# tviic2d6mddr register map
Vendor: Cypress Semiconductor; Series: tviic2d6mddr; File version: 1.0
CPU: CM7 r0p1, little endian, MPU, FPU, VTOR, 3 interrupt priority bits
Registers are 32-bit, read-write, reset 0x0 unless marked. A register's access mark holds for its fields unless they carry their own. Offsets are from the block's base; [hi:lo] are bit positions; lines under a group give offsets from that group; {n}, {i} and the like mark numbered series.

## LPDDR40 (part 2 of 5) — LPDDR4
Base 0x404A0000
0x1000 LPDDR4_CORE group — LPDDR4 core (3PIP)
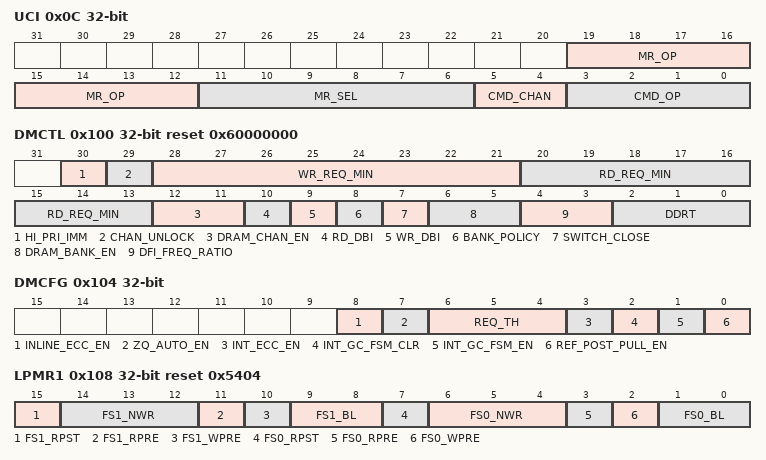
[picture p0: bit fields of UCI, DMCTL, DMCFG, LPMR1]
  0x0C UCI — User Command Interface
    [19:12] MR_OP — Register Opcode (MRW, MPC) See LPDDR4 memory datasheet for definition of opcodes.
    [11:6] MR_SEL — Register Select Argument for MRS/MRW/MRR Command
    [5:4] CMD_CHAN
    [3:0] CMD_OP — User Command Opcode. Valid values are: USER_CMD_STOP = 4'b0000 Stop Normal Operation USER_CMD_RUN = 4'b0001 Start Normal Operation USER_CMD_SRE = 4'b0010 Self-Refresh Mode Entry USER_CMD_SRX = 4'b0011 Self-Refresh Mode Exit USER_CMD_PDE = 4'b0100 Power-Down Mode Entry USER_CMD_PDX = 4'b0101 Power-Down Mode Exit USER_CMD_ZQRS = 4'b0110 ZQ Calibration Reset USER_CMD_MRR = 4'b0111 Mode Register Read USER_CMD_MRW = 4'b1000 Mode Register Write USER_CMD_BIST = 4'b1001 BIST USER_CMD_ZQSTART = 4'b1010 ZQSTART USER_CMD_ZQLAT = 4'b1011 ZQLAT USER_CMD_DQSOSC_START = 4'b1100 Start DQS Oscillator USER_CMD_DQSOSC_STOP = 4'b1101 Stop DQS Oscillator In case an invalid command or an invalid command sequence is detected the controller will enter STOP mode and raise a fault signal if dmcfg.int_gc_fsm_en is enabled.
  0x100 DMCTL reset 0x60000000 — Dynamo Control Register
    [30] HI_PRI_IMM — High priority immediately serving. The Arbiter will grant for the high priority stream immediately. 0: Disabled 1: Enabled
    [29] CHAN_UNLOCK — Channel unlock. A bank requester FSM can be unlocked while it is blocked by the other in the same port. 0: Disabled 1: Enabled
    [28:21] WR_REQ_MIN — Minimum Available Write requests will be served before switching to Read direction
    [20:13] RD_REQ_MIN — Minimum Available Read requests will be served before switching to Write direction
    [12:11] DRAM_CHAN_EN
    [10] RD_DBI — Memory Controller Read Databus Inversion (DBI) Mode Enable/disable coding: DISABLE = 0 Disable this feature ENABLE = 1 Enable this feature
    [9] WR_DBI — Memory Controller Write Databus Inversion (DBI) Mode Enable/disable coding: DISABLE = 0 Disable this feature ENABLE = 1 Enable this feature
    [8] BANK_POLICY — CLOSE_PAGE = 0 Close Page Policy OPEN_PAGE = 1 Open page policy
    [7] SWITCH_CLOSE — Force closing open page when Read/Write direction changes. DONT_CLOSE_ON_RW_CHG = 0 Do not close an open page when Read/Write direction changes on the same page. DO_CLOSE_ON_RW_CHG = 1 Close an open page when Read/Write direction changes on the same page.
    [6:5] DRAM_BANK_EN
    [4:3] DFI_FREQ_RATIO — DFI Frequency Ratio Always write 2'b10 to this register (only frequency ratio 1:4 is supported). DIV_4 = 2'b10 Controller to PHY frequency ratio is 1:4.
    [2:0] DDRT — DDR Type. Always write 3'b111 for LPDDR4. Only LPDDR4 is supported. LPDDR4 = 3'b111 LPDDR4
  0x104 DMCFG — Dynamo Configuration Register
    [8] INLINE_ECC_EN — Inline ECC enable. Enable/disable coding: DISABLE = 0 Disable this feature ENABLE = 1 Enable this feature
    [7] ZQ_AUTO_EN — Automatic ZQ Calibration enable. In case Automatic ZQ Calibration is used, the rate is defined in TREG9.T_ZQ_ITV. Enable/disable coding: DISABLE = 0 Disable this feature ENABLE = 1 Enable this feature
    [6:4] REQ_TH — Look-ahead buffer request threshold
    [3] INT_ECC_EN — ECC interrupt enable signal. Enable/disable coding: DISABLE = 0 Disable this feature ENABLE = 1 Enable this feature
    [2] INT_GC_FSM_CLR — Global FSM Error interrupt clear signal. DONT_CLEAR = 0 Don't clear. DO_CLEAR = 1 Clear. Set int_gc_fsm LOW.
    [1] INT_GC_FSM_EN — Global FSM Error interrupt enable signal. Enable/disable coding: DISABLE = 0 Disable this feature ENABLE = 1 Enable this feature
    [0] REF_POST_PULL_EN — Enables Postpone/Pull Automatic Refresh. Enable/disable coding: DISABLE = 0 Disable this feature ENABLE = 1 Enable this feature
  0x108 LPMR1 reset 0x5404 — LPDDR Mode Register 1
    [15] FS1_RPST — Read postamble for frequency set 1 Read Postamble values according to JESD209-4: RD_POSTAMBLE_0P5 = 0B RD Post-amble = 0.5*tCK (default) RD_POSTAMBLE_1P5 = 1B RD Post-amble = 1.5*tCK
    [14:12] FS1_NWR — Write recovery to pre-charge for frequency set 1 Write Recovery values according to JESD209-4: NWR6 = 000B nWR = 6 (default) NWR10 = 001B nWR = 10 NWR16 = 010B nWR = 16 NWR20 = 011B nWR = 20 NWR24 = 100B nWR = 24 NWR30 = 101B nWR = 30 NWR34 = 110B nWR = 34 NWR40 = 111B nWR = 40
    [11] FS1_RPRE — Read preamble for frequency set 1 Read Preamble values according to JESD209-4: RD_PREAMBLE_STATIC = 0B RD Pre-amble = Static (default) RD_PREAMBLE_TOGGLE = 1B RD Pre-amble = Toggle
    [10] FS1_WPRE
    [9:8] FS1_BL
    [7] FS0_RPST — Read postamble for frequency set 0 Read Postamble values according to JESD209-4: RD_POSTAMBLE_0P5 = 0B RD Post-amble = 0.5*tCK (default) RD_POSTAMBLE_1P5 = 1B RD Post-amble = 1.5*tCK
    [6:4] FS0_NWR — Write recovery to pre-charge for frequency set 0 Write Recovery values according to JESD209-4: NWR6 = 000B nWR = 6 (default) NWR10 = 001B nWR = 10 NWR16 = 010B nWR = 16 NWR20 = 011B nWR = 20 NWR24 = 100B nWR = 24 NWR30 = 101B nWR = 30 NWR34 = 110B nWR = 34 NWR40 = 111B nWR = 40
    [3] FS0_RPRE — Read preamble for frequency set 0 Read Preamble values according to JESD209-4: RD_PREAMBLE_STATIC = 0B RD Pre-amble = Static (default) RD_PREAMBLE_TOGGLE = 1B RD Pre-amble = Toggle
    [2] FS0_WPRE
    [1:0] FS0_BL
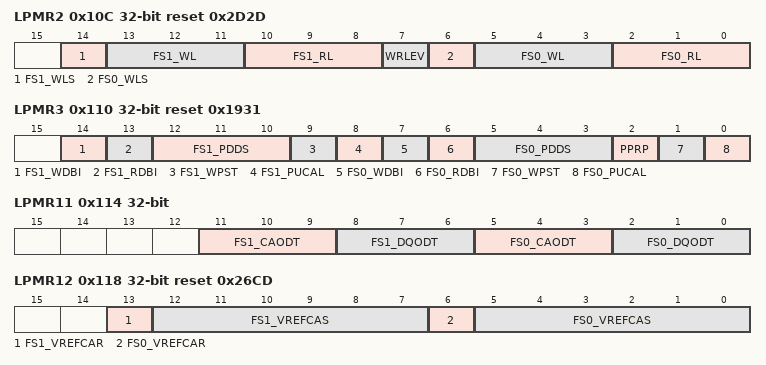
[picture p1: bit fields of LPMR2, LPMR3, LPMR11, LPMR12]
  0x10C LPMR2 reset 0x2D2D — LPDDR Mode Register 2
    [14] FS1_WLS — Write Latency Set values according to JESD209-4: WL_SET_A = 0B WL Set 'A' (default) WL_SET_B = 1B WL Set 'B'
    [13:11] FS1_WL — Write latency for frequency set 1 Write Latency values according to JESD209-4: WL Set 'A' (MR2 OP[6]=0B) 000B: WL=4 (Default) 001B: WL=6 010B: WL=8 011B: WL=10 100B: WL=12 101B: WL=14 110B: WL=16 111B: WL=18 WL Set 'B' (MR2 OP[6]=1B) 000B: WL=4 001B: WL=8 010B: WL=12 011B: WL=18 100B: WL=22 101B: WL=26 110B: WL=30 111B: WL=34
    [10:8] FS1_RL — Read latency for frequency set 1 Read Latency values according to JESD209-4: RL & nRTP for DBI-RD Disabled (MR3 OP[6]=0B) 000B: RL=6, nRTP = 8 (Default) 001B: RL=10, nRTP = 8 010B: RL=14, nRTP = 8 011B: RL=20, nRTP = 8 100B: RL=24, nRTP = 10 101B: RL=28, nRTP = 12 110B: RL=32, nRTP = 14 111B: RL=36, nRTP = 16 RL & nRTP for DBI-RD Enabled (MR3 OP[6]=1B) 000B: RL=6, nRTP = 8 001B: RL=12, nRTP = 8 010B: RL=16, nRTP = 8 011B: RL=22, nRTP = 8 100B: RL=28, nRTP = 10 101B: RL=32, nRTP = 12 110B: RL=36, nRTP = 14 111B: RL=40, nRTP = 16
    [7] WRLEV — Write Leveling Enable Enable/disable coding: DISABLE = 0 Disable this feature ENABLE = 1 Enable this feature
    [6] FS0_WLS — Write Latency Set values according to JESD209-4: WL_SET_A = 0B WL Set 'A' (default) WL_SET_B = 1B WL Set 'B'
    [5:3] FS0_WL — Write latency for frequency set 0 Write Latency values according to JESD209-4: WL Set 'A' (MR2 OP[6]=0B) 000B: WL=4 (Default) 001B: WL=6 010B: WL=8 011B: WL=10 100B: WL=12 101B: WL=14 110B: WL=16 111B: WL=18 WL Set 'B' (MR2 OP[6]=1B) 000B: WL=4 001B: WL=8 010B: WL=12 011B: WL=18 100B: WL=22 101B: WL=26 110B: WL=30 111B: WL=34
    [2:0] FS0_RL — Read latency for frequency set 0 Read Latency values according to JESD209-4: RL & nRTP for DBI-RD Disabled (MR3 OP[6]=0B) 000B: RL=6, nRTP = 8 (Default) 001B: RL=10, nRTP = 8 010B: RL=14, nRTP = 8 011B: RL=20, nRTP = 8 100B: RL=24, nRTP = 10 101B: RL=28, nRTP = 12 110B: RL=32, nRTP = 14 111B: RL=36, nRTP = 16 RL & nRTP for DBI-RD Enabled (MR3 OP[6]=1B) 000B: RL=6, nRTP = 8 001B: RL=12, nRTP = 8 010B: RL=16, nRTP = 8 011B: RL=22, nRTP = 8 100B: RL=28, nRTP = 10 101B: RL=32, nRTP = 12 110B: RL=36, nRTP = 14 111B: RL=40, nRTP = 16
  0x110 LPMR3 reset 0x1931 — LPDDR Mode Register 3
    [14] FS1_WDBI — Write DBI mode for frequency set 1 Values according to JESD209-4: Enable/disable coding: DISABLE = 0 Disable this feature ENABLE = 1 Enable this feature
    [13] FS1_RDBI — Read DBI mode for frequency set 1 Values according to JESD209-4: Enable/disable coding: DISABLE = 0 Disable this feature ENABLE = 1 Enable this feature
    [12:10] FS1_PDDS
    [9] FS1_WPST — Write post-amble for frequency set 1 Write post-amble values according to JESD209-4: WR_POSTAMBLE_0P5 = 0B WR Post-amble = 0.5*tCK (default) WR_POSTAMBLE_1P5 = 1B WR Post-amble = 1.5*tCK (Vendor specific function)
    [8] FS1_PUCAL — Pull-up Calibration point for frequency set 1 Pull-up Calibration point values according to JESD209-4: VDDQ_DIV_2P5 = 0B VDDQ/2.5 VDDQ_DIV_3 = 1B VDDQ/3 (default)
    [7] FS0_WDBI — Write DBI mode for frequency set 0 Values according to JESD209-4: Enable/disable coding: DISABLE = 0 Disable this feature ENABLE = 1 Enable this feature
    [6] FS0_RDBI — Read DBI mode for frequency set 0 Values according to JESD209-4: Enable/disable coding: DISABLE = 0 Disable this feature ENABLE = 1 Enable this feature
    [5:3] FS0_PDDS
    [2] PPRP — Post package repair protection Values according to JESD209-4: Enable/disable coding: DISABLE = 0 Disable this feature ENABLE = 1 Enable this feature
    [1] FS0_WPST — Write post-amble for frequency set 0 Write post-amble values according to JESD209-4: WR_POSTAMBLE_0P5 = 0B WR Post-amble = 0.5*tCK (default) WR_POSTAMBLE_1P5 = 1B WR Post-amble = 1.5*tCK (Vendor specific function)
    [0] FS0_PUCAL — Pull-up Calibration point for frequency set 0 Pull-up Calibration point values according to JESD209-4: VDDQ_DIV_2P5 = 0B VDDQ/2.5 VDDQ_DIV_3 = 1B VDDQ/3 (default)
  0x114 LPMR11 — LPDDR Mode Register 11
    [11:9] FS1_CAODT, [8:6] FS1_DQODT, [5:3] FS0_CAODT, [2:0] FS0_DQODT
  0x118 LPMR12 reset 0x26CD — LPDDR Mode Register 12
    [13] FS1_VREFCAR — VREF-CA range for frequency set 1 VREF Range according to JESD209-4: RANGE0 = 0B Range[0] enabled RANGE1 =1B Range[1] enabled
    [12:7] FS1_VREFCAS — VREF-CA Settings for frequency set 1 VREF-CA Setting values according to JESD209-4: See JESD209-4B Table 13 - VREF Settings for Range[0] and Range[1]
    [6] FS0_VREFCAR — VREF-CA range for frequency set 0 VREF Range according to JESD209-4: RANGE0 = 0B Range[0] enabled RANGE1 =1B Range[1] enabled
    [5:0] FS0_VREFCAS — VREF-CA Settings for frequency set 0 VREF-CA Setting values according to JESD209-4: See JESD209-4B Table 13 - VREF Settings for Range[0] and Range[1]
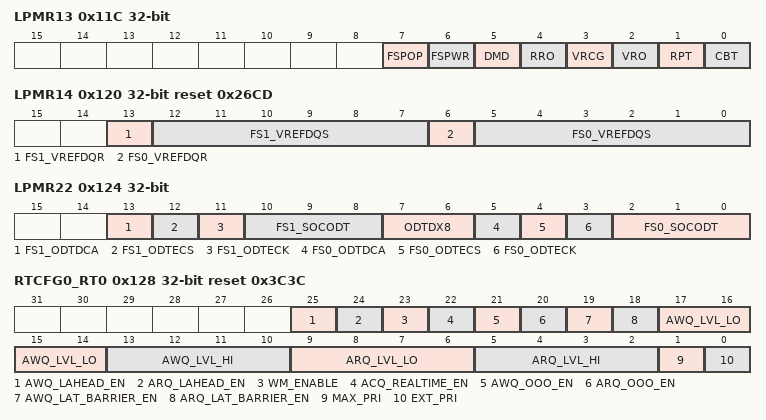
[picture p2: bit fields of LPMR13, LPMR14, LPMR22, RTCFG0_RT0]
  0x11C LPMR13 — LPDDR Mode Register 13
    [7] FSPOP — Frequency Set Point operating mode Frequency Set Point coding according to JESD209-4: FSP0 = 0 Frequency Set Point 0 FSP1 = 1 Frequency Set Point 1
    [6] FSPWR — Frequency Set Point write enable Frequency Set Point coding according to JESD209-4: FSP0 = 0 Frequency Set Point 0 FSP1 = 1 Frequency Set Point 1
    [5] DMD — Data mask disable Data Mask Disable values according to JESD209-4: ENABLED = 0B Data Mask Operation Enabled (default) DISABLED = 1B Data Mask Operation Disabled
    [4] RRO — Refresh rate option Refresh Rate Option values according to JESD209-4: DISABLE_RR4X2X = 0B Disable codes 001 (Refresh Rate x 4) and 010 (Refresh Rate x 2) in MR4 OP[2:0] ENABLE_ALL = 1B Enable all codes in MR4 OP[2:0]
    [3] VRCG — VREF current generator VREF Current Generator values according to JESD209-4: NORMAL = 0B Normal Operation (default) VREF_FAST = 1B VREF Fast Response (high current) mode
    [2] VRO — VREF output enable Enable/disable coding: DISABLE = 0 Disable this feature ENABLE = 1 Enable this feature
    [1] RPT — Read preamble training mode Values according to JESD209-4: Enable/disable coding: DISABLE = 0 Disable this feature ENABLE = 1 Enable this feature
    [0] CBT — Command bus training mode enable Enable/disable coding: DISABLE = 0 Disable this feature ENABLE = 1 Enable this feature
  0x120 LPMR14 reset 0x26CD — LPDDR Mode Register 14
    [13] FS1_VREFDQR — VREF-DQ range for frequency set 1 VREF Range according to JESD209-4: RANGE0 = 0B Range[0] enabled RANGE1 =1B Range[1] enabled
    [12:7] FS1_VREFDQS — VREF-DQ Settings for frequency set 1 VREF-DQ Setting values according to JESD209-4: See JESD209-4B Table 14 - VREF Settings for Range[0] and Range[1]
    [6] FS0_VREFDQR — VREF-DQ range for frequency set 0 VREF Range according to JESD209-4: RANGE0 = 0B Range[0] enabled RANGE1 =1B Range[1] enabled
    [5:0] FS0_VREFDQS — VREF-DQ Settings for frequency set 0 VREF-DQ Setting values according to JESD209-4: See JESD209-4B Table 14 - VREF Settings for Range[0] and Range[1]
  0x124 LPMR22 — LPDDR Mode Register 22
    [13] FS1_ODTDCA — ODTD-CA. CA ODT termination disable for frequency set 1 Command/Address bus ODT termination disable. Values according to JESD209-4: ODT_CA_PAD = 0B ODT-CA Obeys ODT_CA bond pad (default) ODT_CA_DISABLED = 1B ODT-CA Disabled
    [12] FS1_ODTECS — ODTE-CS. CS ODT enable for non-terminating rank for frequency set 1 ODT Enable for non-terminating rank. Values according to JESD209-4: OVERRIDE_DISABLED = 0B ODT-CK Over-ride Disabled (Default) OVERRIDE_ENABLED = 1B ODT-CK Over-ride Enabled
    [11] FS1_ODTECK — ODTE-CK. CK ODT enable for non-terminating rank for frequency set 1 ODT Enable for non-terminating rank. Values according to JESD209-4: OVERRIDE_DISABLED = 0B ODT-CK Over-ride Disabled (Default) OVERRIDE_ENABLED = 1B ODT-CK Over-ride Enabled
    [10:8] FS1_SOCODT — SoC ODT. Controller ODT value for VOH calibration for frequency set 1 Controller ODT values according to JESD209-4: DISABLE = 000B Disable (Default) RZQ_DIV_1 = 001B RZQ/1 RZQ_DIV_2 = 010B RZQ/2 RZQ_DIV_3 = 011B RZQ/3 RZQ_DIV_4 = 100B RZQ/4 RZQ_DIV_5 = 101B RZQ/5 RZQ_DIV_6 = 110B RZQ/6 RFU = 111B RFU
    [7:6] ODTDX8 — ODTD for x8_2ch (byte) mode
    [5] FS0_ODTDCA — ODTD-CA. CA ODT termination disable for frequency set 0 Command/Address bus ODT termination disable. Values according to JESD209-4: ODT_CA_PAD = 0B ODT-CA Obeys ODT_CA bond pad (default) ODT_CA_DISABLED = 1B ODT-CA Disabled
    [4] FS0_ODTECS — ODTE-CS. CS ODT enable for non-terminating rank for frequency set 0 ODT Enable for non-terminating rank. Values according to JESD209-4: OVERRIDE_DISABLED = 0B ODT-CK Over-ride Disabled (Default) OVERRIDE_ENABLED = 1B ODT-CK Over-ride Enabled
    [3] FS0_ODTECK — ODTE-CK. CK ODT enable for non-terminating rank for frequency set 0 ODT Enable for non-terminating rank. Values according to JESD209-4: OVERRIDE_DISABLED = 0B ODT-CK Over-ride Disabled (Default) OVERRIDE_ENABLED = 1B ODT-CK Over-ride Enabled
    [2:0] FS0_SOCODT — SoC ODT. Controller ODT value for VOH calibration for frequency set 0 Controller ODT values according to JESD209-4: DISABLE = 000B Disable (Default) RZQ_DIV_1 = 001B RZQ/1 RZQ_DIV_2 = 010B RZQ/2 RZQ_DIV_3 = 011B RZQ/3 RZQ_DIV_4 = 100B RZQ/4 RZQ_DIV_5 = 101B RZQ/5 RZQ_DIV_6 = 110B RZQ/6 RFU = 111B RFU
  0x128 RTCFG0_RT0 reset 0x3C3C — Route Configuration 0 - Route 0
    [25] AWQ_LAHEAD_EN — Out of order enable for Look-ahead buffer in Write channel - Route 0
    [24] ARQ_LAHEAD_EN — Out of order enable for Look-ahead buffer in read channel - Route 0
    [23] WM_ENABLE — Masked Write Support - Route 0 Enable/disable coding: DISABLE = 0 Disable this feature ENABLE = 1 Enable this feature
    [22] ACQ_REALTIME_EN — Realtime priority enable for Read/Write channel - Route 0 Enable/disable coding: DISABLE = 0 Disable this feature ENABLE = 1 Enable this feature
    [21] AWQ_OOO_EN — Out of order enable for write channel - Route 0 Enable/disable coding: DISABLE = 0 Disable this feature ENABLE = 1 Enable this feature
    [20] ARQ_OOO_EN — Out of order enable for read channel - Route 0 Enable/disable coding: DISABLE = 0 Disable this feature ENABLE = 1 Enable this feature
    [19] AWQ_LAT_BARRIER_EN — Maximum Latency Barrier Enable for Write Channel - Route 0 Enable/disable coding: DISABLE = 0 Disable this feature ENABLE = 1 Enable this feature
    [18] ARQ_LAT_BARRIER_EN — Maximum Latency Barrier Enable for Read Channel - Route 0 Enable/disable coding: DISABLE = 0 Disable this feature ENABLE = 1 Enable this feature
    [17:14] AWQ_LVL_LO — Denotes Write Address Queue Low Priority Threshold - Route 0
    [13:10] AWQ_LVL_HI — Denotes Write Address Queue High Priority Threshold - Route 0
    [9:6] ARQ_LVL_LO — Denotes Read Address Queue Low Priority Threshold - Route 0
    [5:2] ARQ_LVL_HI — Denotes Read Address Queue High Priority Threshold - Route 0
    [1] MAX_PRI — Denotes Static Maximum Priority - Route 0 Enable/disable coding: DISABLE = 0 Disable this feature ENABLE = 1 Enable this feature
    [0] EXT_PRI — Selects whether to use external AXI QoS field or internal combination of static and dynamic priority. STATIC_DYNAMIC = 0 Internal Static or Dynamic Priority used AXI_QOS = 1 AXI QoS used
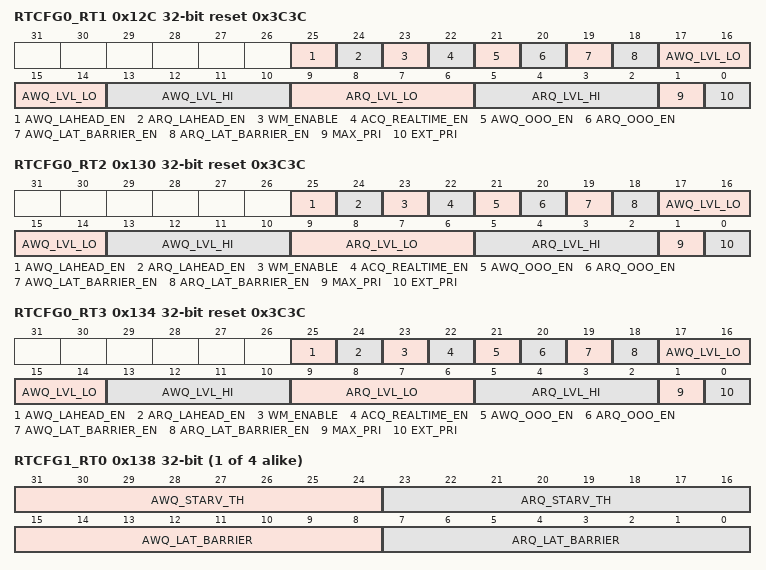
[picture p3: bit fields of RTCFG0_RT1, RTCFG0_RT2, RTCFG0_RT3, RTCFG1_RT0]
  0x12C RTCFG0_RT1 reset 0x3C3C — Route Configuration 0 - Route 1
    [25] AWQ_LAHEAD_EN — Out of order enable for Look-ahead buffer in Write channel - Route 1
    [24] ARQ_LAHEAD_EN — Out of order enable for Look-ahead buffer in read channel - Route 1
    [23] WM_ENABLE — Masked Write Support - Route 1 Enable/disable coding: DISABLE = 0 Disable this feature ENABLE = 1 Enable this feature
    [22] ACQ_REALTIME_EN — Realtime priority enable for Read/Write channel - Route 1 Enable/disable coding: DISABLE = 0 Disable this feature ENABLE = 1 Enable this feature
    [21] AWQ_OOO_EN — Out of order enable for write channel - Route 1 Enable/disable coding: DISABLE = 0 Disable this feature ENABLE = 1 Enable this feature
    [20] ARQ_OOO_EN — Out of order enable for read channel - Route 1 Enable/disable coding: DISABLE = 0 Disable this feature ENABLE = 1 Enable this feature
    [19] AWQ_LAT_BARRIER_EN — Maximum Latency Barrier Enable for Write Channel - Route 1Enable/disable coding: DISABLE = 0 Disable this feature ENABLE = 1 Enable this feature
    [18] ARQ_LAT_BARRIER_EN — Maximum Latency Barrier Enable for Read Channel - Route 1 Enable/disable coding: DISABLE = 0 Disable this feature ENABLE = 1 Enable this feature
    [17:14] AWQ_LVL_LO — Denotes Write Address Queue Low Priority Threshold - Route 1
    [13:10] AWQ_LVL_HI — Denotes Write Address Queue High Priority Threshold - Route 1
    [9:6] ARQ_LVL_LO — Denotes Read Address Queue Low Priority Threshold - Route 1
    [5:2] ARQ_LVL_HI — Denotes Read Address Queue High Priority Threshold - Route 1
    [1] MAX_PRI — Denotes Static Maximum Priority - Route 1 Enable/disable coding: DISABLE = 0 Disable this feature ENABLE = 1 Enable this feature
    [0] EXT_PRI — Selects whether to use external AXI QoS field or internal combination of static and dynamic priority - Route 1 Enable/disable coding: DISABLE = 0 Disable this feature ENABLE = 1 Enable this feature
  0x130 RTCFG0_RT2 reset 0x3C3C — Route Configuration 0 - Route 2
    [25] AWQ_LAHEAD_EN — Out of order enable for Look-ahead buffer in Write channel - Route 2
    [24] ARQ_LAHEAD_EN — Out of order enable for Look-ahead buffer in read channel - Route 2
    [23] WM_ENABLE — Masked Write Support - Route 2 Enable/disable coding: DISABLE = 0 Disable this feature ENABLE = 1 Enable this feature
    [22] ACQ_REALTIME_EN — Realtime priority enable for Read/Write channel - Route 2 Enable/disable coding: DISABLE = 0 Disable this feature ENABLE = 1 Enable this feature
    [21] AWQ_OOO_EN — Out of order enable for write channel - Route 2 Enable/disable coding: DISABLE = 0 Disable this feature ENABLE = 1 Enable this feature
    [20] ARQ_OOO_EN — Out of order enable for read channel - Route 2 Enable/disable coding: DISABLE = 0 Disable this feature ENABLE = 1 Enable this feature
    [19] AWQ_LAT_BARRIER_EN — Maximum Latency Barrier Enable for Write Channel - Route 2 Enable/disable coding: DISABLE = 0 Disable this feature ENABLE = 1 Enable this feature
    [18] ARQ_LAT_BARRIER_EN — Maximum Latency Barrier Enable for Read Channel - Route 2 Enable/disable coding: DISABLE = 0 Disable this feature ENABLE = 1 Enable this feature
    [17:14] AWQ_LVL_LO — Denotes Write Address Queue Low Priority Threshold - Route 2
    [13:10] AWQ_LVL_HI — Denotes Write Address Queue High Priority Threshold - Route 2
    [9:6] ARQ_LVL_LO — Denotes Read Address Queue Low Priority Threshold - Route 2
    [5:2] ARQ_LVL_HI — Denotes Read Address Queue High Priority Threshold - Route 2
    [1] MAX_PRI — Denotes Static Maximum Priority - Route 2 Enable/disable coding: DISABLE = 0 Disable this feature ENABLE = 1 Enable this feature
    [0] EXT_PRI — Selects whether to use external AXI QoS field or internal combination of static and dynamic priority - Route 2 Enable/disable coding: DISABLE = 0 Disable this feature ENABLE = 1 Enable this feature
  0x134 RTCFG0_RT3 reset 0x3C3C — Route Configuration 0 - Route 3
    [25] AWQ_LAHEAD_EN — Out of order enable for Look-ahead buffer in Write channel - Route 3
    [24] ARQ_LAHEAD_EN — Out of order enable for Look-ahead buffer in read channel - Route 3
    [23] WM_ENABLE — Masked Write Support - Route 3 Enable/disable coding: DISABLE = 0 Disable this feature ENABLE = 1 Enable this feature
    [22] ACQ_REALTIME_EN — Realtime priority enable for Read/Write channel - Route 3 Enable/disable coding: DISABLE = 0 Disable this feature ENABLE = 1 Enable this feature
    [21] AWQ_OOO_EN — Out of order enable for write channel - Route 3 Enable/disable coding: DISABLE = 0 Disable this feature ENABLE = 1 Enable this feature
    [20] ARQ_OOO_EN — Out of order enable for read channel - Route 3 Enable/disable coding: DISABLE = 0 Disable this feature ENABLE = 1 Enable this feature
    [19] AWQ_LAT_BARRIER_EN — Maximum Latency Barrier Enable for Write Channel - Route 3 Enable/disable coding: DISABLE = 0 Disable this feature ENABLE = 1 Enable this feature
    [18] ARQ_LAT_BARRIER_EN — Maximum Latency Barrier Enable for Read Channel - Route 3 Enable/disable coding: DISABLE = 0 Disable this feature ENABLE = 1 Enable this feature
    [17:14] AWQ_LVL_LO — Denotes Write Address Queue Low Priority Threshold - Route 3
    [13:10] AWQ_LVL_HI — Denotes Write Address Queue High Priority Threshold - Route 3
    [9:6] ARQ_LVL_LO — Denotes Read Address Queue Low Priority Threshold - Route 3
    [5:2] ARQ_LVL_HI — Denotes Read Address Queue High Priority Threshold - Route 3
    [1] MAX_PRI — Denotes Static Maximum Priority - Route 3 Enable/disable coding: DISABLE = 0 Disable this feature ENABLE = 1 Enable this feature
    [0] EXT_PRI — Selects whether to use external AXI QoS field or internal combination of static and dynamic priority - Route 3 Enable/disable coding: DISABLE = 0 Disable this feature ENABLE = 1 Enable this feature
  {0x138+4j} RTCFG1_RT{j} (j=0..3) — Route Configuration 1 - Route {j}
    [31:24] AWQ_STARV_TH — Denotes Write Address Queue Threshold for starvation preventing. Its value represents the number of hits in a hit chain - Route {j}
    [23:16] ARQ_STARV_TH — Denotes Read Address Queue Threshold for starvation preventing. Its value represents the number of hits in a hit chain - Route {j}
    [15:8] AWQ_LAT_BARRIER — Maximum Latency Barrier for Write Channel - Route {j}
    [7:0] ARQ_LAT_BARRIER — Maximum Latency Barrier for Read Channel - Route {j}
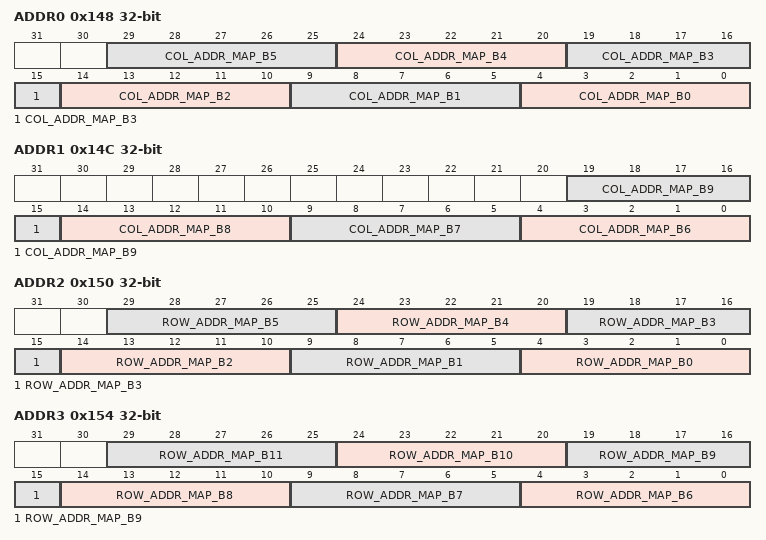
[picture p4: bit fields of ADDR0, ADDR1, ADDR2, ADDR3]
  0x148 ADDR0 — DRAM Address Register 0
    [5n+4:5n] COL_ADDR_MAP_B{n} (n=0..5) — Address mapping for column bit {n}
  0x14C ADDR1 — DRAM Address Register 1
    [5n-26:5n-30] COL_ADDR_MAP_B{n} (n=6..9) — Address mapping for column bit {n}
  0x150 ADDR2 — DRAM Address Register 2
    [5n+4:5n] ROW_ADDR_MAP_B{n} (n=0..5) — Address mapping for row bit {n}
  0x154 ADDR3 — DRAM Address Register 3
    [5n-26:5n-30] ROW_ADDR_MAP_B{n} (n=6..11) — Address mapping for row bit {n}
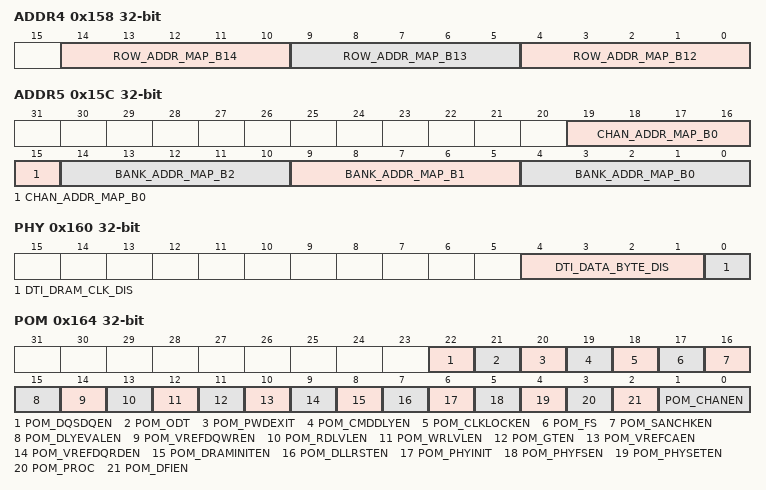
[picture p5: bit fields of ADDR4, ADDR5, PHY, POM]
  0x158 ADDR4 — DRAM Address Register 4
    [14:10] ROW_ADDR_MAP_B14 — Address mapping for row bit 14
    [9:5] ROW_ADDR_MAP_B13 — Address mapping for row bit 13
    [4:0] ROW_ADDR_MAP_B12 — Address mapping for row bit 12
  0x15C ADDR5 — DRAM Address Register 5
    [19:15] CHAN_ADDR_MAP_B0 — Address mapping for channel bit 0
    [14:10] BANK_ADDR_MAP_B2 — Address mapping for bank bit 2
    [9:5] BANK_ADDR_MAP_B1 — Address mapping for bank bit 1
    [4:0] BANK_ADDR_MAP_B0 — Address mapping for bank bit 0
  0x160 PHY
    [4:1] DTI_DATA_BYTE_DIS — Signal to disable operations on the specified byte-lane dti_data_byte_dis[0] = 0: Enable byte-lane 0 dti_data_byte_dis[0] = 1: Disable byte-lane 0 ... dti_data_byte_dis[3] = 0: Enable byte-lane 3 dti_data_byte_dis[3] = 1: Disable byte-lane 3
    [0] DTI_DRAM_CLK_DIS — This register is used by the MC to inform the PHY when to enable/disable the clock to the memory device Enable/disable coding: DISABLE = 0 Disable this feature ENABLE = 1 Enable this feature
  0x164 POM — PHY Operation Mode Register
    [22] POM_DQSDQEN — tDQS2DQ retraining enable. For handling tDQS2DQ shifting.Enable/disable coding: DISABLE = 0 Disable this feature ENABLE = 1 Enable this feature
    [21] POM_ODT — On Die Termination (ODT) control flag.Enable/disable coding: DISABLE = 0 Disable this feature ENABLE = 1 Enable this feature
    [20] POM_PWDEXIT — Exit from power-down indicator flag
    [19] POM_CMDDLYEN — Load PHY command bus delay To help PHY debugging, DTI PHY supports user to set timing delay for its memory control and address signals. This feature is also to meet CA/CS setup and hold time in slow frequency operation. To enable PHY command delay load, user must write 1'b1 to cmddlyen and phyinit field in POM register. The completion of this process is indicated via cmddlyc field in POS register. After loading process is completed, user must write 1'b0 to cmddlyen field. cmddlyen must be combined with physeten to reload trained setting since physeten does not set for command bus. In this case user must write PHY setting to PTSR* registers then write 1'b1 to cmddlyen, physeten and phyinit fields in POM register. Enable/disable coding: DISABLE = 0 Disable this feature ENABLE = 1 Enable this feature
    [18] POM_CLKLOCKEN — MC-PHY clock phase lock request. When running in 1:4 mode user must write 1'b1 to clklocken field in POM register along with dllrsten and phyinit, this enables phase lock mechanism inside the PHY. User must clear this field when writing 1'b0 to phyinit field. Enable/disable coding: DISABLE = 0 Disable this feature ENABLE = 1 Enable this feature
    [17] POM_FS — Target Frequency Set-point for PHY operations. Must be different from operating set point. FS0 = 0 Frequency Set Point 0 FS1 = 1 Frequency Set Point 1
    [16] POM_SANCHKEN — Write/read sanity check enable.Enable/disable coding: DISABLE = 0 Disable this feature ENABLE = 1 Enable this feature
    [15] POM_DLYEVALEN — Delay evaluation enable. Delay evaluation process must be performed when there is at least one DDR chip with CK-DQS delay exceeding 1 clock cycle. If all DDR chips have CK-DQS delay smaller than 1 clock cycle, this process is not needed. This process can be enabled by writing 1'b1 to dlyevalen field and phyinit field in POM register. The completion of this process is identified by dlyevalc field in POS register. After evaluation is completed, user must write 1'b0 to dlyevalen field and phyinit. Enable/disable coding: DISABLE = 0 Disable this feature ENABLE = 1 Enable this feature
    [14] POM_VREFDQWREN — DRAM VREF-DQ training enable.Enable/disable coding: DISABLE = 0 Disable this feature ENABLE = 1 Enable this feature
    [13] POM_RDLVLEN — Read data eye DQ training enable.Enable/disable coding: DISABLE = 0 Disable this feature ENABLE = 1 Enable this feature
    [12] POM_WRLVLEN — Write leveling enable.Enable/disable coding: DISABLE = 0 Disable this feature ENABLE = 1 Enable this feature
    [11] POM_GTEN — Gate training enable. The PHY built-in gate training is triggered using POM_GTEN and POM_PHYINIT field in thePOM. Its completion is indicated through bit GTC in the POS. The field GTERR in the PTS0 shows gate training error for each Data Module in the PHY while training. After DQS gate training is completed, user must write 1'b0 to POM_GTE and POM_PHYINIT. The error is asserted when the PHY doesn't provide HIGH on GT_STATUS. Enable/disable coding: DISABLE = 0 Disable this feature ENABLE = 1 Enable this feature
    [10] POM_VREFCAEN — DRAM VREF-CA training enable. Enable/disable coding: DISABLE = 0 Disable this feature ENABLE = 1 Enable this feature
    [9] POM_VREFDQRDEN — PHY VREF-DQ training enable. The PHY built-in VREF-DQ training is triggered using vrefdqrden and phyinit field in the POM. Its completion is indicated through bit vrefdqrdc in thePOS. The field vrefdqrderr in the PTS0 shows that the PHY cannot find correct VREF setting for its internal receiver after training. The error is asserted if the PHY doesn't assert VT_DONE. The PHY looks at the voltage high level during VREF-DQ training. If (voltage_high/2) is beyond the VREF generation specification then VT_DONE won't assert. After PHY VREF-DQ training is completed, user must write 1'b0 to verfdqrden and phyinit field. Enable/disable coding: DISABLE = 0 Disable this feature ENABLE = 1 Enable this feature
    [8] POM_DRAMINITEN — DRAM initialization enable The PHY built-in DRAM initialization is triggered using draminiten and phyinit fields in the POM - PHY Operation Mode Register. Its completion is indicated through bit draminitc in the POS - PHY Operation Status Register. The DRAM mode registers and timing registers must be configured correctly prior to triggering DRAM initialization, even if user chooses not to use the built-in initialization. Enable/disable coding: DISABLE = 0 Disable this feature ENABLE = 1 Enable this feature
    [7] POM_DLLRSTEN — DLL reset enable.Enable/disable coding: DISABLE = 0 Disable this feature ENABLE = 1 Enable this feature
    [6] POM_PHYINIT — PHY initialization enable. PHY initialization includes DLL init, DRAM init, and PHY training. Software can do each step separately by writing other bits in this register individually.Enable/disable coding: DISABLE = 0 Disable this feature ENABLE = 1 Enable this feature
    [5] POM_PHYFSEN — PHY frequency change enable To switch Frequency Set-point, user must write 1'b1 to phyfsen and phyinit field in POM register with target Frequency Set-point in fs field. fs value must be different from operating Frequency Set-point. User can obtain operating Frequency Set-point by reading ofs field in POS register. The completion of this process is indicated through phyfsc field in the POS. After this process is completed, user must write 1'b0 to phyfsen and phyinit. Enable/disable coding: DISABLE = 0 Disable this feature ENABLE = 1 Enable this feature
    [4] POM_PHYSETEN — PHY setting reload enable To reduce PHY start-up time, DTI PHY supports a process called 'PHY setting reload' to put the PHY to normal operation mode without performing any time-consumed training process. To enable PHY setting reload process, user must write 1'b1 to physeten field in POM register. The completion of this process is indicated through physetc field in POS register. After reload process is completed, user must write 1'b0 to physeten field. Enable/disable coding: DISABLE = 0 Disable this feature ENABLE = 1 Enable this feature
    [3] POM_PROC — PHY operation proceed. MC must write 1'b1 to this field when request from the PHY is satisfied. Enable/disable coding: DISABLE = 0 Disable this feature ENABLE = 1 Enable this feature
    [2] POM_DFIEN — DFI interface enable. After training, MC must write 1'b1 to this field for normal DFI operation. Enable/disable coding: DISABLE = 0 Disable this feature ENABLE = 1 Enable this feature
    [1:0] POM_CHANEN — LPDDR4 channel enable for training. CHAN_NO = 2'b00 Enable no channel CHAN_0 = 2'b01 Enable channel 0 CHAN_1 = 2'b10 Enable channel 1 CHAN_BOTH = 2'b11 Enable channel 0 and channel 1
